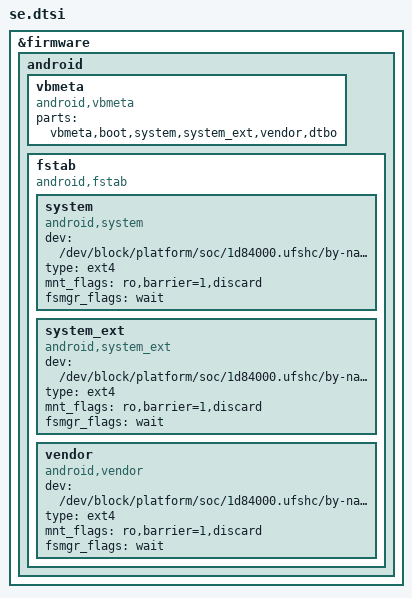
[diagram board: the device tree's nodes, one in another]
/*
 * DT fstab -- variant: SE (System-Ext).
 *
 * Same as the NSE variant (see nse.dtsi for the full explanation of why
 * Android 10/11 needs the fstab inside the DTB), plus one system_ext entry.
 *
 * Xiaomi SDM845 devices have no partition literally named "system_ext"; SE
 * roms use the "cust" partition (the MIUI regional customisation one) as
 * /system_ext. That is the convention LineageOS uses for these devices, so the
 * entry below points at /by-name/cust, not at /by-name/system_ext.
 *
 * If your SE rom uses a real system_ext partition (from a repartition), this
 * entry points at the wrong device and boot fails. Roms like that are almost
 * always dynamic-partition builds already and should use the "DYNAMIC" variant.
 *
 * vbmeta.parts is extended with system_ext so the bootloader's partition list
 * matches the SE layout.
 */

&firmware {
	android {
		vbmeta {
			compatible = "android,vbmeta";
			parts = "vbmeta,boot,system,system_ext,vendor,dtbo";
		};

		fstab {
			compatible = "android,fstab";

			system {
				compatible = "android,system";
				dev = "/dev/block/platform/soc/1d84000.ufshc/by-name/system";
				type = "ext4";
				mnt_flags = "ro,barrier=1,discard";
				fsmgr_flags = "wait";
				status = "ok";
			};

			system_ext {
				compatible = "android,system_ext";
				dev = "/dev/block/platform/soc/1d84000.ufshc/by-name/cust";
				type = "ext4";
				mnt_flags = "ro,barrier=1,discard";
				fsmgr_flags = "wait";
				status = "ok";
			};

			vendor {
				compatible = "android,vendor";
				dev = "/dev/block/platform/soc/1d84000.ufshc/by-name/vendor";
				type = "ext4";
				mnt_flags = "ro,barrier=1,discard";
				fsmgr_flags = "wait";
				status = "ok";
			};
		};
	};
};
